# APM32M35XX register map
File version: 1.0
Registers are 32-bit, read-write, reset 0x0 unless marked. A register's access mark holds for its fields unless they carry their own. Offsets are from the block's base; [hi:lo] are bit positions; {n}, {i} and the like mark numbered series; 'fields as' and 'values as' point back to an identical list.

## CAN — Controller area network
Base 0x40006400
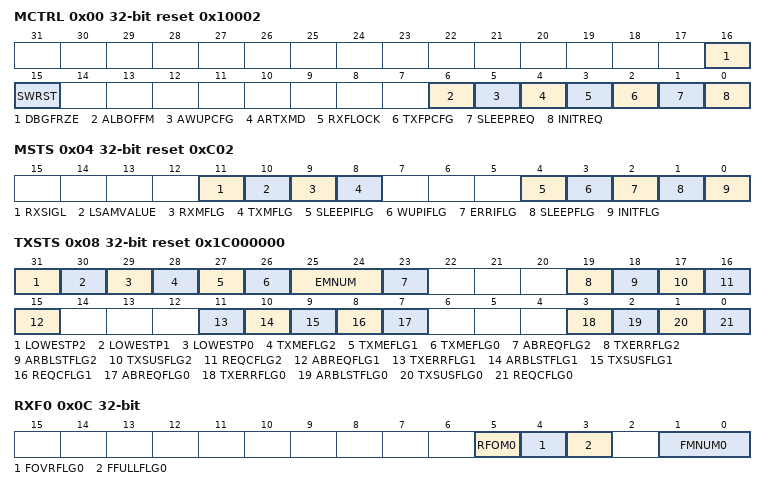
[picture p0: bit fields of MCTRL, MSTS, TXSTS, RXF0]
0x00 MCTRL reset 0x10002 — CAN master control register
  [16] DBGFRZE — Debug freeze
  [15] SWRST — software master reset
  [6] ALBOFFM — Automatic bus-off management
  [5] AWUPCFG — Automatic wakeup mode
  [4] ARTXMD — No automatic retransmission
  [3] RXFLOCK — Receive FIFO locked mode
  [2] TXFPCFG — Transmit FIFO priority
  [1] SLEEPREQ — Sleep mode request
  [0] INITREQ — Initialization request
0x04 MSTS access per field reset 0xC02 — CAN master status register
  [11] RXSIGL ro — CAN Rx signal
  [10] LSAMVALUE ro — Last sample point
  [9] RXMFLG ro — Receive mode
  [8] TXMFLG ro — Transmit mode
  [4] SLEEPIFLG rw — Sleep acknowledge interrupt
  [3] WUPIFLG rw — Wakeup interrupt
  [2] ERRIFLG rw — Error interrupt
  [1] SLEEPFLG ro — Sleep acknowledge
  [0] INITFLG ro — Initialization acknowledge
0x08 TXSTS access per field reset 0x1C000000 — CAN transmit status register
  [31] LOWESTP2 ro — Lowest priority flag for mailbox2
  [30] LOWESTP1 ro — Lowest priority flag for mailbox1
  [29] LOWESTP0 ro — Lowest priority flag for mailbox0
  [28] TXMEFLG2 ro — Transmit mailbox 2 empty
  [27] TXMEFLG1 ro — Transmit mailbox 1 empty
  [26] TXMEFLG0 ro — Transmit mailbox 0 empty
  [25:24] EMNUM ro — Mailbox code
  [23] ABREQFLG2 rw — Abort request for mailbox 2
  [19] TXERRFLG2 rw — Transmission error of mailbox 2
  [18] ARBLSTFLG2 rw — Arbitration lost for mailbox 2
  [17] TXSUSFLG2 rw — Transmission OK of mailbox 2
  [16] REQCFLG2 rw — Request completed mailbox 2
  [15] ABREQFLG1 rw — Abort request for mailbox 1
  [11] TXERRFLG1 rw — Transmission error of mailbox 1
  [10] ARBLSTFLG1 rw — Arbitration lost for mailbox 1
  [9] TXSUSFLG1 rw — Transmission OK of mailbox 1
  [8] REQCFLG1 rw — Request completed mailbox 1
  [7] ABREQFLG0 rw — Abort request for mailbox 0
  [3] TXERRFLG0 rw — Transmission error of mailbox 0
  [2] ARBLSTFLG0 rw — Arbitration lost for mailbox 0
  [1] TXSUSFLG0 rw — Transmission OK of mailbox .
  [0] REQCFLG0 rw — Request completed mailbox 0
0x0C RXF0 access per field — CAN receive FIFO 0 register
  [5] RFOM0 rw — Release FIFO 0 output mailbox
  [4] FOVRFLG0 rw — FIFO 0 overrun
  [3] FFULLFLG0 rw — FIFO 0 full
  [1:0] FMNUM0 ro — FIFO 0 message pending
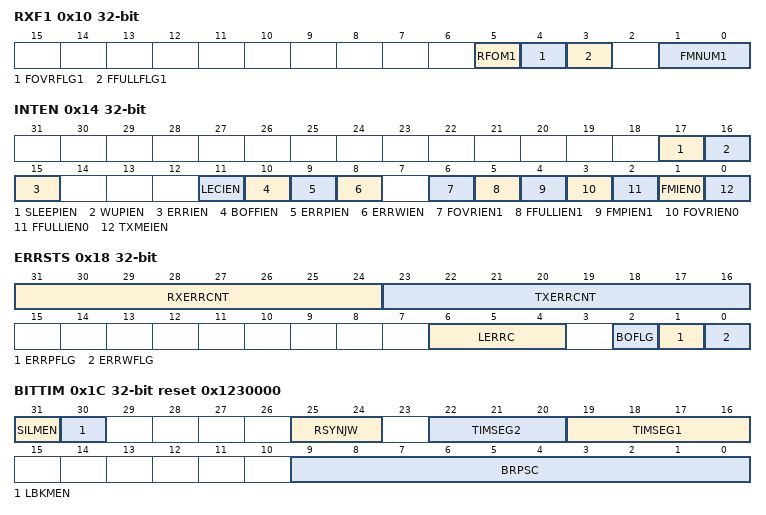
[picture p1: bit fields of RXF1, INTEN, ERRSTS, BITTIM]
0x10 RXF1 access per field — CAN receive FIFO 1 register
  [5] RFOM1 rw — Release FIFO 1 output mailbox
  [4] FOVRFLG1 rw — FIFO 1 overrun
  [3] FFULLFLG1 rw — FIFO 1 full
  [1:0] FMNUM1 ro — FIFO 1 message pending
0x14 INTEN — CAN interrupt enable register
  [17] SLEEPIEN — Sleep interrupt enable
  [16] WUPIEN — Wakeup interrupt enable
  [15] ERRIEN — Error interrupt enable
  [11] LECIEN — Last error code interrupt enable
  [10] BOFFIEN — Bus-off interrupt enable
  [9] ERRPIEN — Error passive interrupt enable
  [8] ERRWIEN — Error warning interrupt enable
  [6] FOVRIEN1 — FIFO overrun interrupt enable
  [5] FFULLIEN1 — FIFO full interrupt enable
  [4] FMPIEN1 — FIFO message pending interrupt enable
  [3] FOVRIEN0 — FIFO overrun interrupt enable
  [2] FFULLIEN0 — FIFO full interrupt enable
  [1] FMIEN0 — FIFO message pending interrupt enable
  [0] TXMEIEN — Transmit mailbox empty interrupt enable
0x18 ERRSTS access per field — CAN error status register
  [31:24] RXERRCNT ro — Receive error counter
  [23:16] TXERRCNT ro — Transmit error counter
  [6:4] LERRC rw — Last error code
  [2] BOFLG ro — Bus-off flag
  [1] ERRPFLG ro — Error passive flag
  [0] ERRWFLG ro — Error warning flag
0x1C BITTIM reset 0x1230000 — CAN bit timing register
  [31] SILMEN — Silent mode (debug)
  [30] LBKMEN — Loop back mode (debug)
  [25:24] RSYNJW — Resynchronization jump width
  [22:20] TIMSEG2 — Time segment 2
  [19:16] TIMSEG1 — Time segment 1
  [9:0] BRPSC — Baud rate prescaler
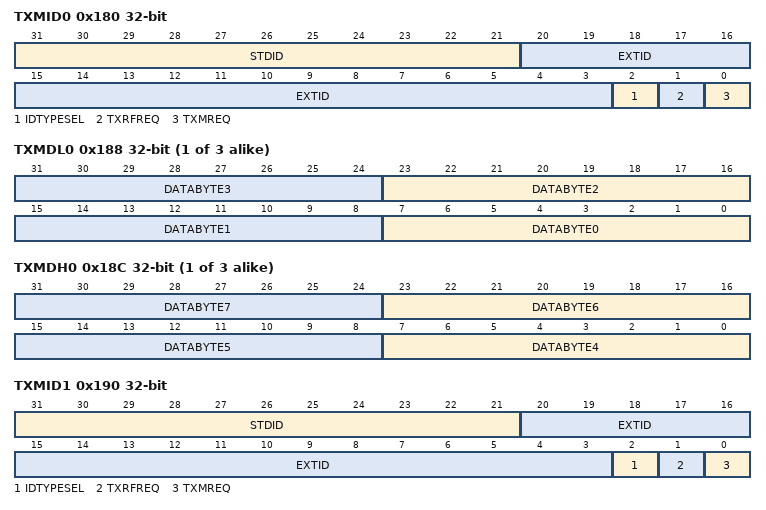
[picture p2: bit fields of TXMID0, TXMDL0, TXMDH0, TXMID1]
0x180 TXMID0 — CAN TX mailbox 0 identifier register
  [31:21] STDID — Standard identifier or extended identifier
  [20:3] EXTID — Extended identifier
  [2] IDTYPESEL — Identifier extension
  [1] TXRFREQ — Remote transmission request
  [0] TXMREQ — Transmit mailbox request
{0x184+0x10*i} TXDLEN{i} (i=0..2) — CAN mailbox {i} data length control and time stamp register
  [3:0] DLCODE — Data length code
{0x188+0x10*i} TXMDL{i} (i=0..2) — CAN mailbox {i} data low register
  [8n+7:8n] DATABYTE{n} (n=0..3)
{0x18C+0x10*i} TXMDH{i} (i=0..2) — CAN mailbox {i} data high register
  [8n-25:8n-32] DATABYTE{n} (n=4..7)
0x190 TXMID1 — CAN TX mailbox 1 identifier register
  fields as TXMID0
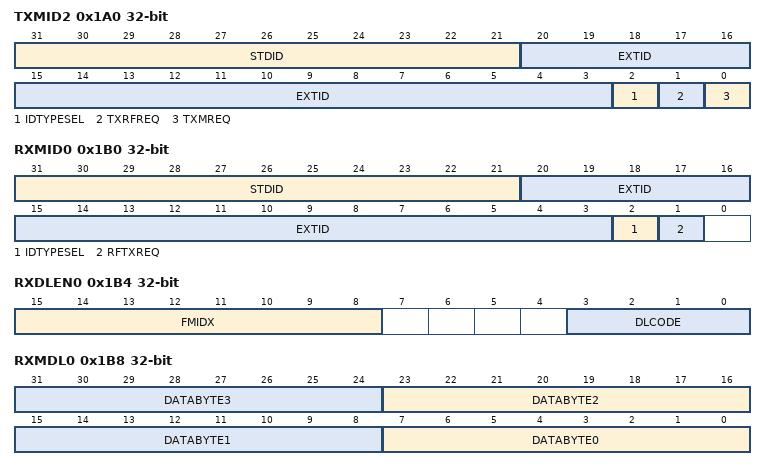
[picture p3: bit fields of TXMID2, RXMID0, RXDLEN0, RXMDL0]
0x1A0 TXMID2 — CAN TX mailbox 0 identifier register
  fields as TXMID0
0x1B0 RXMID0 ro — CAN receive FIFO 0 mailbox identifier register
  [31:21] STDID — Standard identifier or extended identifier
  [20:3] EXTID — Extended identifier
  [2] IDTYPESEL — Identifier extension
  [1] RFTXREQ — Remote transmission request
0x1B4 RXDLEN0 ro — CAN receive FIFO 0 mailbox data length control and time stamp register
  [15:8] FMIDX — Filter match index
  [3:0] DLCODE — Data length code
0x1B8 RXMDL0 ro — CAN receive FIFO 0 mailbox data low register
  [8n+7:8n] DATABYTE{n} (n=0..3)
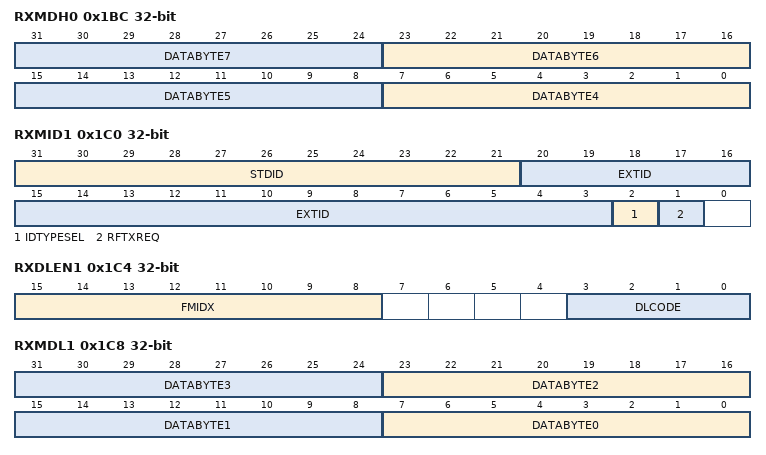
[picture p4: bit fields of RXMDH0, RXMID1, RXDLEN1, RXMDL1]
0x1BC RXMDH0 ro — CAN receive FIFO 0 mailbox data high register
  [8n-25:8n-32] DATABYTE{n} (n=4..7)
0x1C0 RXMID1 ro — CAN receive FIFO 1 mailbox identifier register
  fields as RXMID0
0x1C4 RXDLEN1 ro — CAN receive FIFO 1 mailbox data length control and time stamp register
  [15:8] FMIDX — Filter match index
  [3:0] DLCODE — Data length code
0x1C8 RXMDL1 ro — CAN receive FIFO 1 mailbox data low register
  [8n+7:8n] DATABYTE{n} (n=0..3)
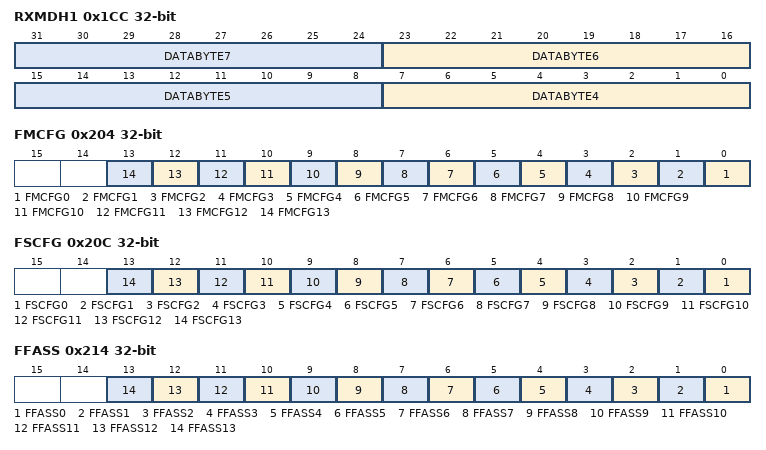
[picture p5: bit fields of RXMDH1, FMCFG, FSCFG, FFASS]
0x1CC RXMDH1 ro — CAN receive FIFO 1 mailbox data high register
  [8n-25:8n-32] DATABYTE{n} (n=4..7)
0x200 FCTRL reset 0x2A1C0E01 — CAN filter master register
  [0] FINITEN — Filter initialization mode
0x204 FMCFG — CAN filter mode register
  [n] FMCFG{n} (n=0..13) — Filter {n} mode
0x20C FSCFG — CAN filter scale register
  [n] FSCFG{n} (n=0..13) — Filter {n} scale configuration
0x214 FFASS — CAN filter FIFO assignment register
  [n] FFASS{n} (n=0..13) — Filter FIFO assignment for filter {n}
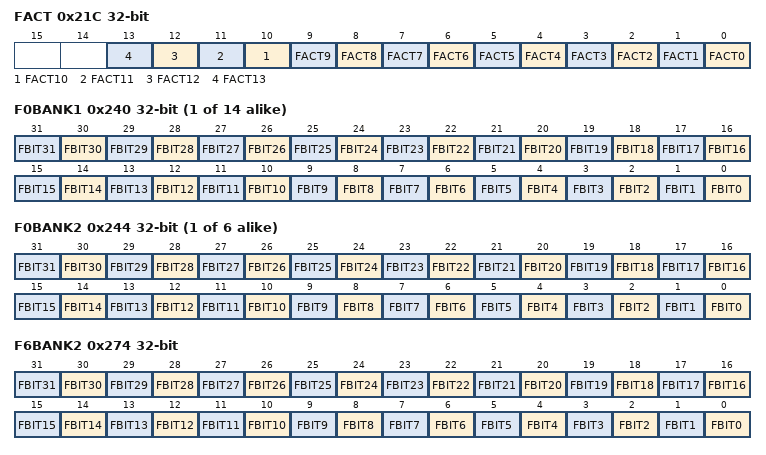
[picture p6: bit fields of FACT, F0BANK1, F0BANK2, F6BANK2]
0x21C FACT — CAN filter activation register
  [n] FACT{n} (n=0..13) — Filter active
{0x240+8i} F{i}BANK1 (i=0..13) — Filter bank {i} register 1
  [n] FBIT{n} (n=0..31) — Filter bits
{0x244+8i} F{i}BANK2 (i=0..5) — Filter bank {i} register 2
  [n] FBIT{n} (n=0..31) — Filter bits
0x274 F6BANK2 — Filter bank 6 register 1
  [n] FBIT{n} (n=0..31) — Filter bits
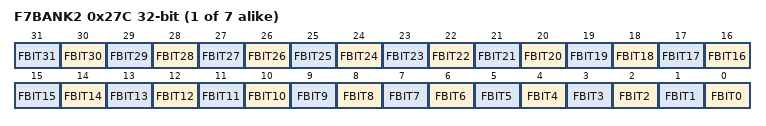
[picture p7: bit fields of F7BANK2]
{0x244+8i} F{i}BANK2 (i=7..13) — Filter bank {i} register 2
  [n] FBIT{n} (n=0..31) — Filter bits
